# CC3220SF register map
Vendor: Texas Instruments; Series: Wireless Connectivity MCU; File version: 1
CPU: CM4 r1p0, little endian, no MPU, no FPU, 8 interrupt priority bits
Registers are 32-bit, read-write, reset 0x0 unless marked. A register's access mark holds for its fields unless they carry their own. Offsets are from the block's base; [hi:lo] are bit positions; {n}, {i} and the like mark numbered series.

## ARCM
Base 0x44025000
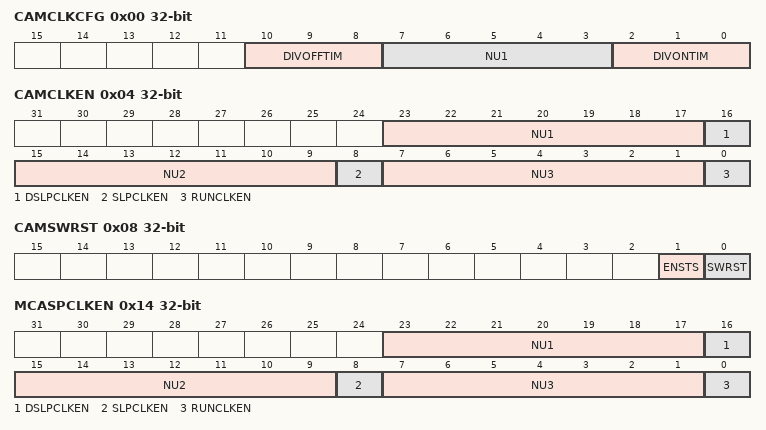
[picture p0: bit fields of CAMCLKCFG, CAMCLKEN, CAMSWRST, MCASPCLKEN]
0x00 CAMCLKCFG
  [10:8] DIVOFFTIM — Configuration of OFF-TIME for dividing PLL clk (240 MHz) in generation of Camera func-clk : "000" - 1 "001" - 2 "010" - 3 "011" - 4 "100" - 5 "101" - 6 "110" - 7 "111" - 8
  [7:3] NU1 ro
  [2:0] DIVONTIM — Configuration of ON-TIME for dividing PLL clk (240 MHz) in generation of Camera func-clk : "000" - 1 "001" - 2 "010" - 3 "011" - 4 "100" - 5 "101" - 6 "110" - 7 "111" - 8
0x04 CAMCLKEN
  [23:17] NU1 ro
  [16] DSLPCLKEN ro — CAMERA_DSLP_CLK_ENABLE
  [15:9] NU2 ro
  [8] SLPCLKEN — CAMERA_SLP_CLK_ENABLE
  [7:1] NU3 ro
  [0] RUNCLKEN — CAMERA_RUN_CLK_ENABLE
0x08 CAMSWRST
  [1] ENSTS ro — CAMERA_ENABLED_STATUS
  [0] SWRST — CAMERA_SOFT_RESET
0x14 MCASPCLKEN
  [23:17] NU1 ro
  [16] DSLPCLKEN ro — MCASP_DSLP_CLK_ENABLE
  [15:9] NU2 ro
  [8] SLPCLKEN — MCASP_SLP_CLK_ENABLE
  [7:1] NU3 ro
  [0] RUNCLKEN — MCASP_RUN_CLK_ENABLE
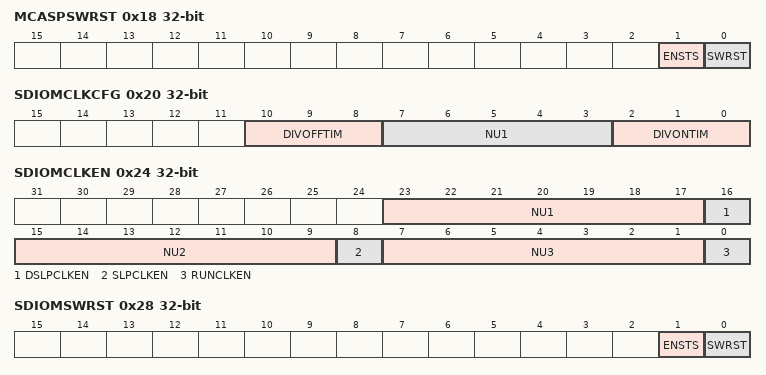
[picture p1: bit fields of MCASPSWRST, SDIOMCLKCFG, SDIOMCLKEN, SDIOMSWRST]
0x18 MCASPSWRST
  [1] ENSTS ro — MCASP_ENABLED_STATUS
  [0] SWRST — MCASP_SOFT_RESET
0x20 SDIOMCLKCFG
  [10:8] DIVOFFTIM — Configuration of OFF-TIME for dividing PLL clk (240 MHz) in generation of MMCHS func-clk : "000" - 1 "001" - 2 "010" - 3 "011" - 4 "100" - 5 "101" - 6 "110" - 7 "111" - 8
  [7:3] NU1
  [2:0] DIVONTIM — Configuration of ON-TIME for dividing PLL clk (240 MHz) in generation of MMCHS func-clk : "000" - 1 "001" - 2 "010" - 3 "011" - 4 "100" - 5 "101" - 6 "110" - 7 "111" - 8
0x24 SDIOMCLKEN
  [23:17] NU1 ro
  [16] DSLPCLKEN ro — MMCHS_DSLP_CLK_ENABLE
  [15:9] NU2 ro
  [8] SLPCLKEN — MMCHS_SLP_CLK_ENABLE
  [7:1] NU3 ro
  [0] RUNCLKEN — MMCHS_RUN_CLK_ENABLE
0x28 SDIOMSWRST
  [1] ENSTS ro — MMCHS_ENABLED_STATUS
  [0] SWRST — MMCHS_SOFT_RESET
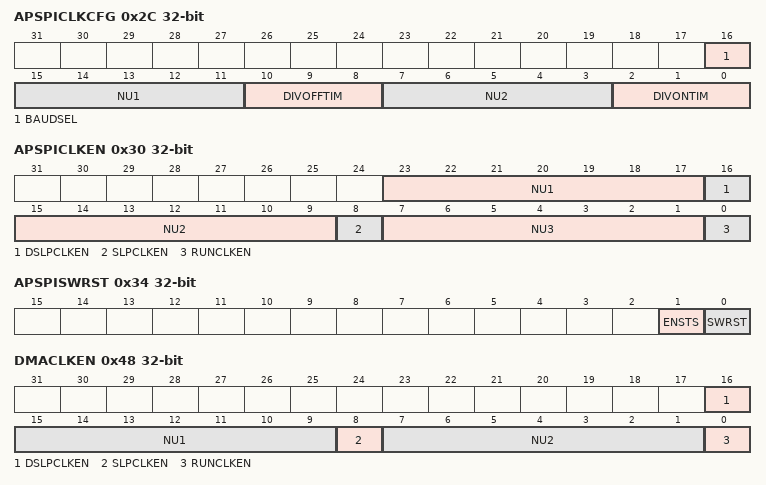
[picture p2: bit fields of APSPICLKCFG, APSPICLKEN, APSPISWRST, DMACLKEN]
0x2C APSPICLKCFG
  [16] BAUDSEL — MCSPI_A1_BAUD_CLK_SEL
  [15:11] NU1 ro
  [10:8] DIVOFFTIM — Configuration of OFF-TIME for dividing PLL clk (240 MHz) in generation of MCSPI_A1 func-clk : "000" - 1 "001" - 2 "010" - 3 "011" - 4 "100" - 5 "101" - 6 "110" - 7 "111" - 8
  [7:3] NU2 ro
  [2:0] DIVONTIM — Configuration of ON-TIME for dividing PLL clk (240 MHz) in generation of MCSPI_A1 func-clk : "000" - 1 "001" - 2 "010" - 3 "011" - 4 "100" - 5 "101" - 6 "110" - 7 "111" - 8
0x30 APSPICLKEN
  [23:17] NU1 ro — Not used
  [16] DSLPCLKEN ro — MCSPI_A1_DSLP_CLK_ENABLE
  [15:9] NU2 ro — Not used
  [8] SLPCLKEN — MCSPI_A1_SLP_CLK_ENABLE
  [7:1] NU3 ro — Not used
  [0] RUNCLKEN — MCSPI_A1_RUN_CLK_ENABLE
0x34 APSPISWRST
  [1] ENSTS ro — MCSPI_A1_ENABLED_STATUS
  [0] SWRST — MCSPI_A1_SOFT_RESET
0x48 DMACLKEN
  [16] DSLPCLKEN — UDMA_A_DSLP_CLK_ENABLE
  [15:9] NU1 ro — Not used
  [8] SLPCLKEN — UDMA_A_SLP_CLK_ENABLE
  [7:1] NU2 ro — Not used
  [0] RUNCLKEN — UDMA_A_RUN_CLK_ENABLE
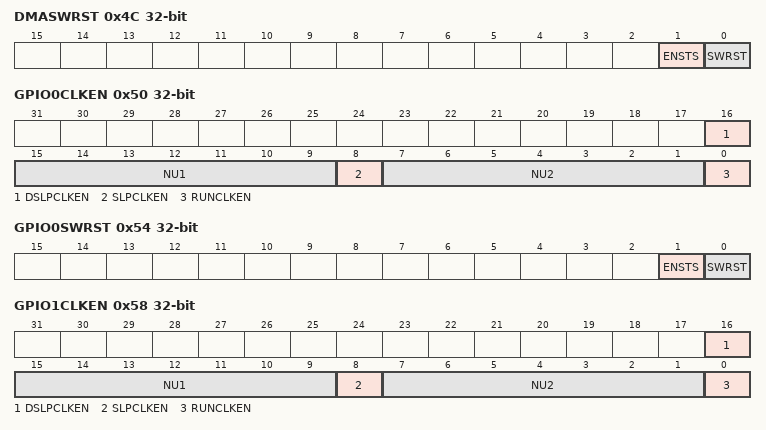
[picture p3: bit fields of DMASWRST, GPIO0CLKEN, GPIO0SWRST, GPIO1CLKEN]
0x4C DMASWRST
  [1] ENSTS ro — UDMA_A_ENABLED_STATUS
  [0] SWRST — UDMA_A_SOFT_RESET
0x50 GPIO0CLKEN
  [16] DSLPCLKEN — GPIO_A_DSLP_CLK_ENABLE
  [15:9] NU1
  [8] SLPCLKEN — GPIO_A_SLP_CLK_ENABLE
  [7:1] NU2
  [0] RUNCLKEN — GPIO_A_RUN_CLK_ENABLE
0x54 GPIO0SWRST
  [1] ENSTS ro — GPIO_A_ENABLED_STATUS
  [0] SWRST — GPIO_A_SOFT_RESET
0x58 GPIO1CLKEN
  [16] DSLPCLKEN — GPIO_B_DSLP_CLK_ENABLE
  [15:9] NU1 ro
  [8] SLPCLKEN — GPIO_B_SLP_CLK_ENABLE
  [7:1] NU2 ro
  [0] RUNCLKEN — GPIO_B_RUN_CLK_ENABLE
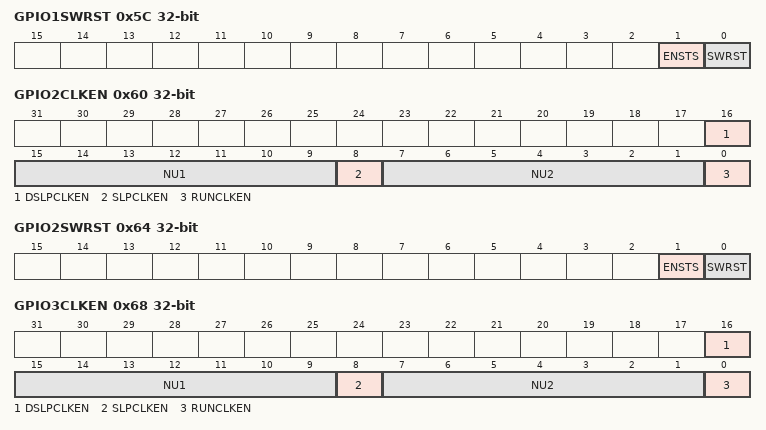
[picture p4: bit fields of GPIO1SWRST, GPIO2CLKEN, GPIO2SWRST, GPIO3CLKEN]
0x5C GPIO1SWRST
  [1] ENSTS ro — GPIO_B_ENABLED_STATUS
  [0] SWRST — GPIO_B_SOFT_RESET
0x60 GPIO2CLKEN
  [16] DSLPCLKEN — GPIO_C_DSLP_CLK_ENABLE
  [15:9] NU1 ro
  [8] SLPCLKEN — GPIO_C_SLP_CLK_ENABLE
  [7:1] NU2 ro
  [0] RUNCLKEN — GPIO_C_RUN_CLK_ENABLE
0x64 GPIO2SWRST
  [1] ENSTS ro — GPIO_C_ENABLED_STATUS
  [0] SWRST — GPIO_C_SOFT_RESET
0x68 GPIO3CLKEN
  [16] DSLPCLKEN — GPIO_D_DSLP_CLK_ENABLE
  [15:9] NU1 ro
  [8] SLPCLKEN — GPIO_D_SLP_CLK_ENABLE
  [7:1] NU2 ro
  [0] RUNCLKEN — GPIO_D_RUN_CLK_ENABLE
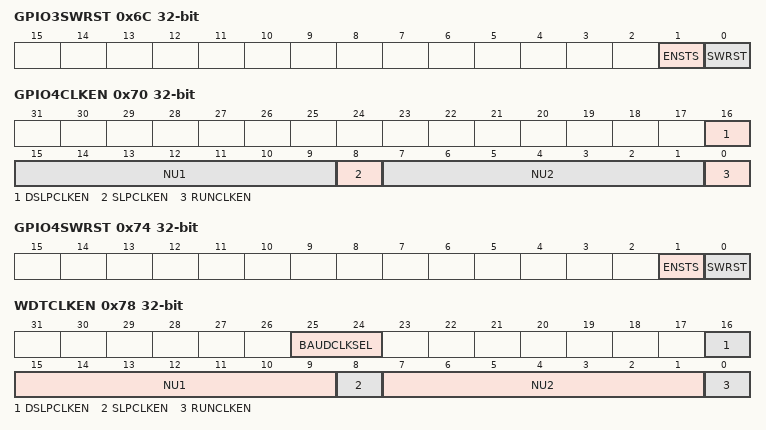
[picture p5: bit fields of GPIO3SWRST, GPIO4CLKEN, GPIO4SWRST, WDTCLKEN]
0x6C GPIO3SWRST
  [1] ENSTS ro — GPIO_D_ENABLED_STATUS
  [0] SWRST — GPIO_D_SOFT_RESET
0x70 GPIO4CLKEN
  [16] DSLPCLKEN — GPIO_E_DSLP_CLK_ENABLE
  [15:9] NU1 ro
  [8] SLPCLKEN — GPIO_E_SLP_CLK_ENABLE
  [7:1] NU2 ro
  [0] RUNCLKEN — GPIO_E_RUN_CLK_ENABLE
0x74 GPIO4SWRST
  [1] ENSTS ro — GPIO_E_ENABLED_STATUS
  [0] SWRST — GPIO_E_SOFT_RESET
0x78 WDTCLKEN
  [25:24] BAUDCLKSEL — "00" - Sysclk ; "01" - REF_CLK (38.4 MHz) ; "10/11" - Slow_clk
  [16] DSLPCLKEN — WDOG_A_DSLP_CLK_ENABLE
  [15:9] NU1 ro
  [8] SLPCLKEN — WDOG_A_SLP_CLK_ENABLE
  [7:1] NU2 ro
  [0] RUNCLKEN — WDOG_A_RUN_CLK_ENABLE
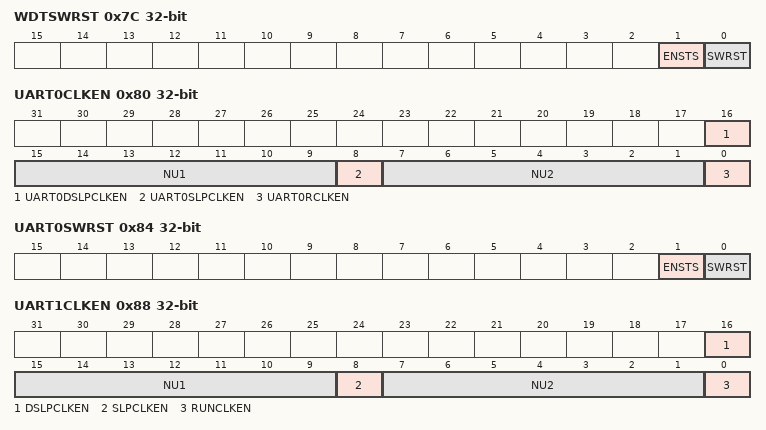
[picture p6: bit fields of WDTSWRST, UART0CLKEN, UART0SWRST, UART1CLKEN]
0x7C WDTSWRST
  [1] ENSTS ro — WDOG_A_ENABLED_STATUS
  [0] SWRST — WDOG_A_SOFT_RESET
0x80 UART0CLKEN
  [16] UART0DSLPCLKEN — UART_A0_DSLP_CLK_ENABLE
  [15:9] NU1 ro
  [8] UART0SLPCLKEN — UART_A0_SLP_CLK_ENABLE
  [7:1] NU2 ro
  [0] UART0RCLKEN — UART_A0_RUN_CLK_ENABLE
0x84 UART0SWRST
  [1] ENSTS ro — UART_A0_ENABLED_STATUS
  [0] SWRST — UART_A0_SOFT_RESET
0x88 UART1CLKEN
  [16] DSLPCLKEN — UART_A1_DSLP_CLK_ENABLE
  [15:9] NU1 ro
  [8] SLPCLKEN — UART_A1_SLP_CLK_ENABLE
  [7:1] NU2 ro
  [0] RUNCLKEN — UART_A1_RUN_CLK_ENABLE
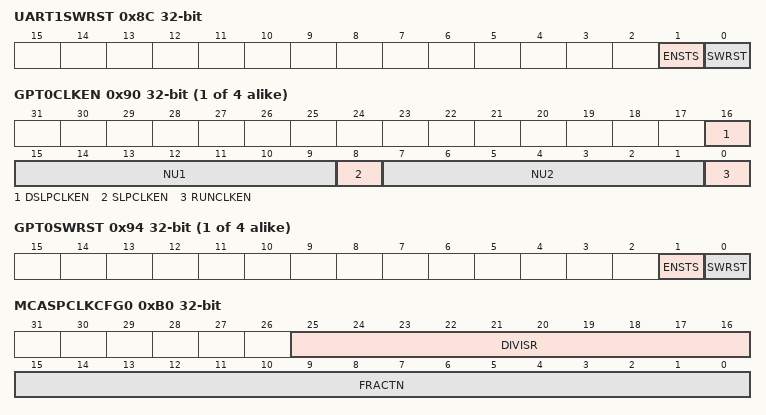
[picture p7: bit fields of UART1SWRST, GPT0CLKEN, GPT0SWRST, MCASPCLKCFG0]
0x8C UART1SWRST
  [1] ENSTS ro — UART_A1_ENABLED_STATUS
  [0] SWRST — UART_A1_SOFT_RESET
{0x90+8i} GPT{i}CLKEN (i=0..3)
  [16] DSLPCLKEN — GPT_A{i}_DSLP_CLK_ENABLE
  [15:9] NU1 ro
  [8] SLPCLKEN — GPT_A{i}_SLP_CLK_ENABLE
  [7:1] NU2 ro
  [0] RUNCLKEN — GPT_A{i}_RUN_CLK_ENABLE
{0x94+8i} GPT{i}SWRST (i=0..3)
  [1] ENSTS ro — GPT_A{i}_ENABLED_STATUS
  [0] SWRST — GPT_A{i}_SOFT_RESET
0xB0 MCASPCLKCFG0
  [25:16] DIVISR — MCASP_FRAC_DIV_DIVISOR
  [15:0] FRACTN — MCASP_FRAC_DIV_FRACTION
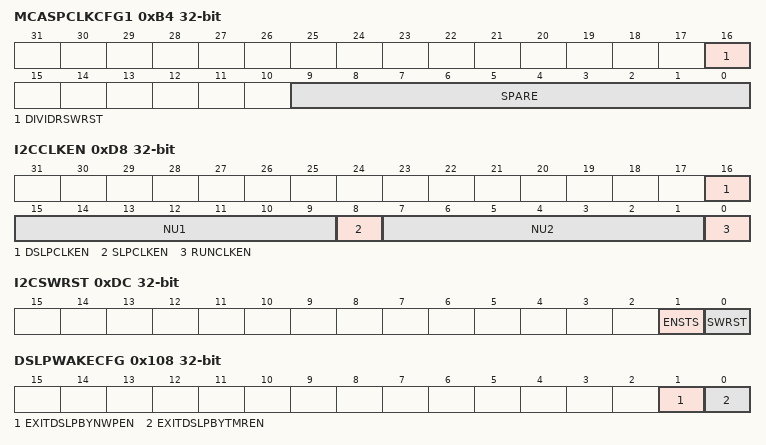
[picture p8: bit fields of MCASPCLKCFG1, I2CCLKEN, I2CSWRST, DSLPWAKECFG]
0xB4 MCASPCLKCFG1
  [16] DIVIDRSWRST — MCASP_FRAC_DIV_SOFT_RESET
  [9:0] SPARE — MCASP_FRAC_DIV_PERIOD
0xD8 I2CCLKEN
  [16] DSLPCLKEN — I2C_DSLP_CLK_ENABLE
  [15:9] NU1 ro
  [8] SLPCLKEN — I2C_SLP_CLK_ENABLE
  [7:1] NU2 ro
  [0] RUNCLKEN — I2C_RUN_CLK_ENABLE
0xDC I2CSWRST
  [1] ENSTS ro — I2C_ENABLED_STATUS
  [0] SWRST — I2C_SOFT_RESET
0xE4 LPDSREQ
  [0] LPDSREQ — APPS_LPDS_REQ
0xEC TURBOREQ
  [0] TURBOREQ — APPS_TURBO_REQ
0x108 DSLPWAKECFG
  [1] EXITDSLPBYNWPEN — DSLP_WAKE_FROM_NWP_ENABLE
  [0] EXITDSLPBYTMREN — DLSP_WAKE_FROM_TIMER_ENABLE
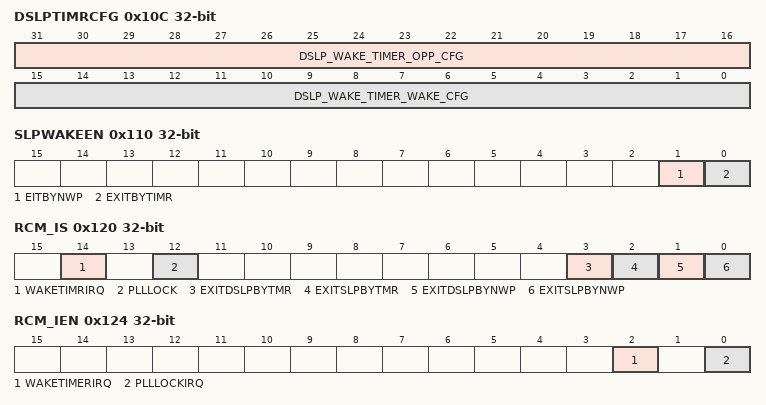
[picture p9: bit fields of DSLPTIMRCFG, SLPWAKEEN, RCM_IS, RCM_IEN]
0x10C DSLPTIMRCFG
  [31:16] DSLP_WAKE_TIMER_OPP_CFG — Configuration (in slow_clks) which says when to request for OPP during deep-sleep exit
  [15:0] DSLP_WAKE_TIMER_WAKE_CFG — Configuration (in slow_clks) which says when to request for WAKE during deep-sleep exit
0x110 SLPWAKEEN
  [1] EITBYNWP — SLP_WAKE_FROM_NWP_ENABLE
  [0] EXITBYTIMR — SLP_WAKE_TIMER_ENABLE
0x114 SLPTMRCFG
  [31:0] TMRCFG — SLP_WAKE_TIMER_CFG
0x118 WAKENWP
  [0] WAKENWP — APPS_TO_NWP_WAKEUP_REQUEST
0x120 RCM_IS
  [14] WAKETIMRIRQ ro, [12] PLLLOCK ro, [3] EXITDSLPBYTMR ro, [2] EXITSLPBYTMR ro, [1] EXITDSLPBYNWP ro, [0] EXITSLPBYNWP ro
0x124 RCM_IEN
  [2] WAKETIMERIRQ, [0] PLLLOCKIRQ
